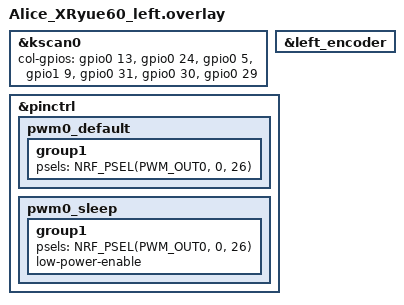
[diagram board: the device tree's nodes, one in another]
/*
 * Copyright (c) 2020 Derek Schmell
 *
 * SPDX-License-Identifier: MIT
 */

#include "Alice_XRyue60.dtsi"

&kscan0 {
    col-gpios
		= <&gpio0 13 GPIO_ACTIVE_HIGH>
                , <&gpio0 24 GPIO_ACTIVE_HIGH>
		, <&gpio0 5 GPIO_ACTIVE_HIGH>
		, <&gpio1 9 GPIO_ACTIVE_HIGH>			
		, <&gpio0 31 GPIO_ACTIVE_HIGH>
		, <&gpio0 30 GPIO_ACTIVE_HIGH>
		, <&gpio0 29 GPIO_ACTIVE_HIGH>
        ;
};
&left_encoder {
    status = "okay";
};

&pinctrl {
    // Other pinctrl definitions for other hardware
    pwm0_default: pwm0_default {
        group1 {
            psels = <NRF_PSEL(PWM_OUT0, 0, 26)>;
        };
    };
    pwm0_sleep: pwm0_sleep {
        group1 {
            psels = <NRF_PSEL(PWM_OUT0, 0, 26)>;
            low-power-enable;
        };
    };
};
